# STM32U5F9 register map
File version: 1.1
CPU: CM33 r0p1, little endian, MPU, FPU, 4 interrupt priority bits
Registers are 32-bit, read-write, reset 0x0 unless marked. A register's access mark holds for its fields unless they carry their own. Offsets are from the block's base; [hi:lo] are bit positions; {n}, {i} and the like mark numbered series.

## DLYBOS1 — The delay block (DLYB) is used to generate an output clock that is dephased from the input clock
Base 0x420CF000
Same registers: DLYBSD1 0x420C8400, DLYBSD2 0x420C8800, DLYBOS2 0x420CF400, SEC_DLYBSD1 0x520C8400, SEC_DLYBSD2 0x520C8800, SEC_DLYBOS1 0x520CF000, SEC_DLYBOS2 0x520CF400
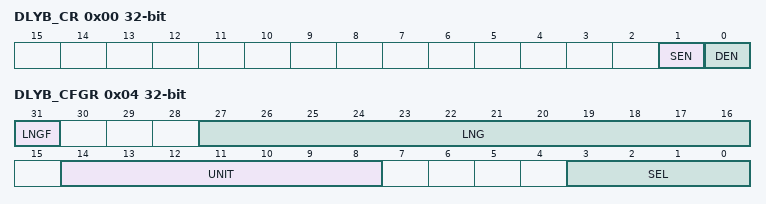
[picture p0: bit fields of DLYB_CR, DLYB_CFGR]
0x00 DLYB_CR — control register
  [1] SEN — OPALPM
  [0] DEN — Operational amplifier Enable
0x04 DLYB_CFGR access per field — configuration register
  [31] LNGF ro, [27:16] LNG ro, [14:8] UNIT rw, [3:0] SEL rw

## EXTI — External interrupt/event
Base 0x46022000
Same registers: SEC_EXTI 0x56022000
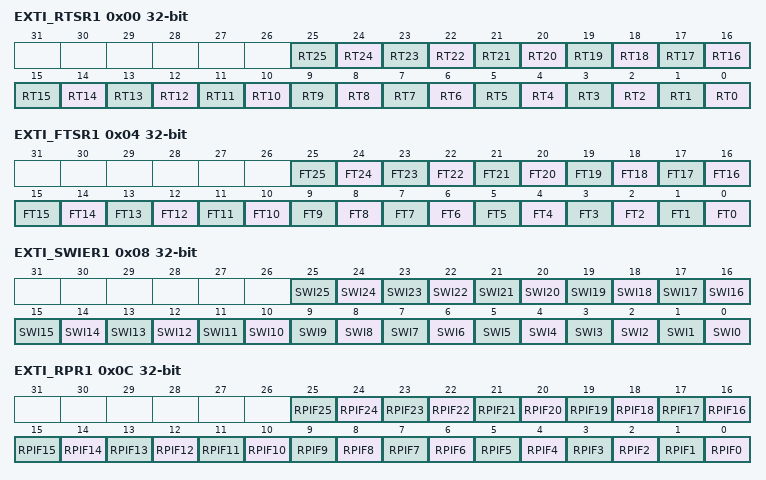
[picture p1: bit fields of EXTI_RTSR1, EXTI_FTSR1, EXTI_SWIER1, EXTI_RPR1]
0x00 EXTI_RTSR1 — EXTI rising trigger selection register
  [all] fields
    0=Rising trigger disabled (for event and interrupt) for input line; 1=Rising trigger enabled (for event and interrupt) for input line
  [n] RT{n} (n=0..25) — Rising trigger event configuration bit of configurable event input x
0x04 EXTI_FTSR1 — EXTI falling trigger selection register
  [all] fields
    0=Falling trigger disabled (for event and interrupt) for input line; 1=Falling trigger enabled (for event and interrupt) for input line
  [n] FT{n} (n=0..25) — Falling trigger event configuration bit of configurable event input x
0x08 EXTI_SWIER1 — EXTI software interrupt event register
  [all] fields
    0=Writing 0 has no effect; 1=Writing 1 triggers a rising edge event on event x. This bit is auto cleared by hardware.
  [n] SWI{n} (n=0..25) — Software interrupt on event x
0x0C EXTI_RPR1 — EXTI rising edge pending register
  [all] fields
    0=No rising edge trigger request occurred; 1=Rising edge trigger request occurred
  [n] RPIF{n} (n=0..25) — configurable event inputs x rising edge pending bit
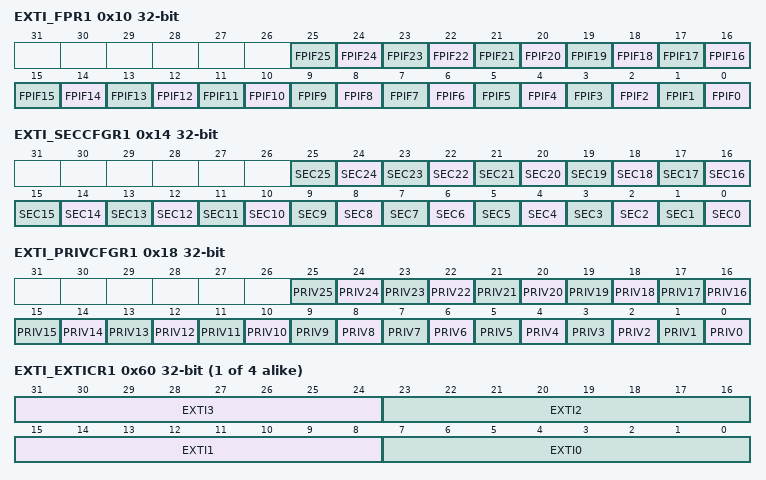
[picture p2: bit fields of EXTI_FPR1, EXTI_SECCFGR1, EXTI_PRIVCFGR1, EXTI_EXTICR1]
0x10 EXTI_FPR1 — EXTI falling edge pending register
  [all] fields
    0=No falling edge trigger request occurred; 1=Falling edge trigger request occurred
  [n] FPIF{n} (n=0..25) — configurable event inputs x falling edge pending bit
0x14 EXTI_SECCFGR1 — EXTI security configuration register
  [all] fields
    0=Event security disabled (non-secure); 1=Event security enabled (secure)
  [n] SEC{n} (n=0..25) — Security enable on event input x
0x18 EXTI_PRIVCFGR1 — EXTI privilege configuration register
  [all] fields
    0=Event privilege disabled (unprivileged); 1=Event privilege enabled (privileged)
  [n] PRIV{n} (n=0..25) — Security enable on event input x
{0x5C+4i} EXTI_EXTICR{i} (i=1..4) — EXTI external interrupt selection register
  [31:24] EXTI{4i-1} — EXTIm+3 GPIO port selection
  [23:16] EXTI{4i-2} — EXTIm+2 GPIO port selection
  [15:8] EXTI{4i-3} — EXTIm+1 GPIO port selection
  [7:0] EXTI{4i-4} — EXTIm GPIO port selection
0x70 EXTI_LOCKR — EXTI lock register
  [0] LOCK — Global security and privilege configuration registers (EXTI_SECCFGR and EXTI_PRIVCFGR) lock
    0=Security and privilege configuration open, can be modified; 1=Security and privilege configuration locked, can no longer be modified
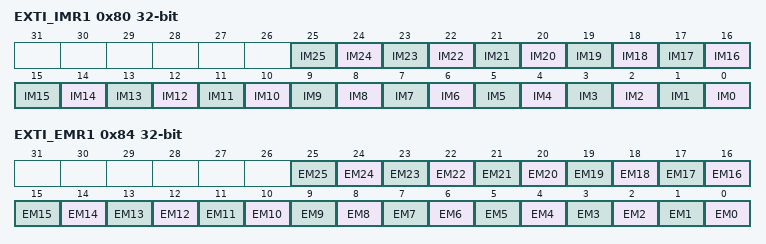
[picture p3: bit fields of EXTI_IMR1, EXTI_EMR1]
0x80 EXTI_IMR1 — EXTI CPU wake-up with interrupt mask register
  [all] fields
    0=Wake-up with interrupt request from input event x is masked; 1=Wake-up with interrupt request from input event x is unmasked
  [n] IM{n} (n=0..25) — CPU wake-up with interrupt mask on event input x
0x84 EXTI_EMR1 — EXTI CPU wake-up with event mask register
  [all] fields
    0=Wake-up with event generation from line x is masked; 1=Wake-up with event generation from line x is unmasked
  [n] EM{n} (n=0..25) — CPU wake-up with event generation mask on event input x

## FMAC — Filter Math Accelerator
Base 0x40021400
Same registers: SEC_FMAC 0x50021400
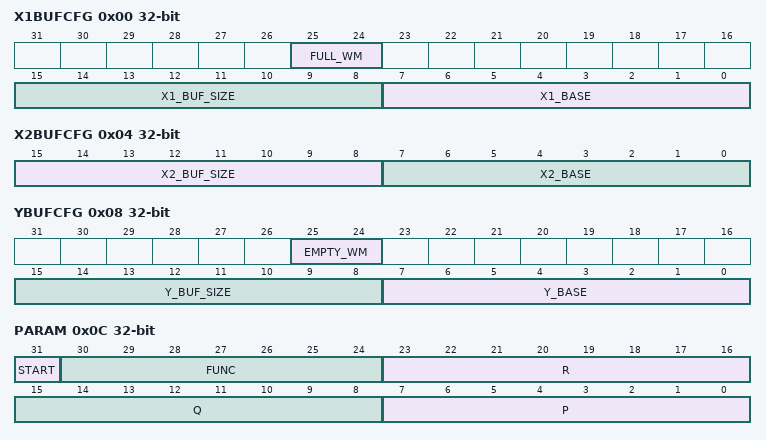
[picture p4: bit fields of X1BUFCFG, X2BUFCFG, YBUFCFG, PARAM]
0x00 X1BUFCFG — FMAC X1 Buffer Configuration register
  [25:24] FULL_WM — Watermark for buffer full flag
  [15:8] X1_BUF_SIZE — Allocated size of X1 buffer in 16-bit words
  [7:0] X1_BASE — Base address of X1 buffer
0x04 X2BUFCFG — FMAC X2 Buffer Configuration register
  [15:8] X2_BUF_SIZE — Size of X2 buffer in 16-bit words
  [7:0] X2_BASE — Base address of X2 buffer
0x08 YBUFCFG — FMAC Y Buffer Configuration register
  [25:24] EMPTY_WM — Watermark for buffer empty flag
  [15:8] Y_BUF_SIZE — Size of Y buffer in 16-bit words
  [7:0] Y_BASE — Base address of Y buffer
0x0C PARAM — FMAC Parameter register
  [31] START — Enable execution
  [30:24] FUNC — Function
  [23:16] R — Input parameter R
  [15:8] Q — Input parameter Q
  [7:0] P — Input parameter P
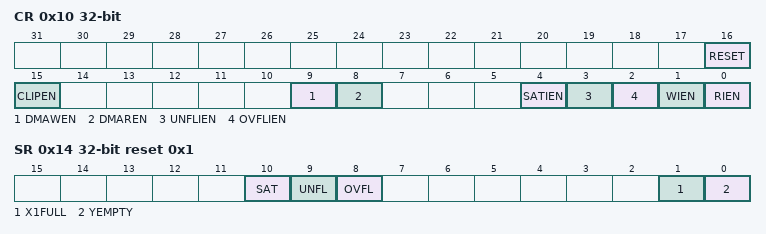
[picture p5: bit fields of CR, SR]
0x10 CR — FMAC Control register
  [16] RESET — Reset FMAC unit
  [15] CLIPEN — Enable clipping
  [9] DMAWEN — Enable DMA write channel requests
  [8] DMAREN — Enable DMA read channel requests
  [4] SATIEN — Enable saturation error interrupts
  [3] UNFLIEN — Enable underflow error interrupts
  [2] OVFLIEN — Enable overflow error interrupts
  [1] WIEN — Enable write interrupt
  [0] RIEN — Enable read interrupt
0x14 SR ro reset 0x1 — FMAC Status register
  [10] SAT — Saturation error flag
  [9] UNFL — Underflow error flag
  [8] OVFL — Overflow error flag
  [1] X1FULL — X1 buffer full flag
  [0] YEMPTY — Y buffer empty flag
0x18 WDATA wo — FMAC Write Data register
  [15:0] WDATA — Write data
0x1C RDATA ro — FMAC Read Data register
  [15:0] RDATA — Read data

## Notices in the file
Copyright (c) 2024 STMicroelectronics.
SPDX-License-Identifier: Apache-2.0
Licensed under the Apache License, Version 2.0 (the "License");
you may not use this file except in compliance with the License.
You may obtain a copy of the License at
http://www.apache.org/licenses/LICENSE-2.0
Unless required by applicable law or agreed to in writing, software
distributed under the License is distributed on an "AS IS" BASIS,
WITHOUT WARRANTIES OR CONDITIONS OF ANY KIND, either express or implied.
See the License for the specific language governing permissions and
limitations under the License.
